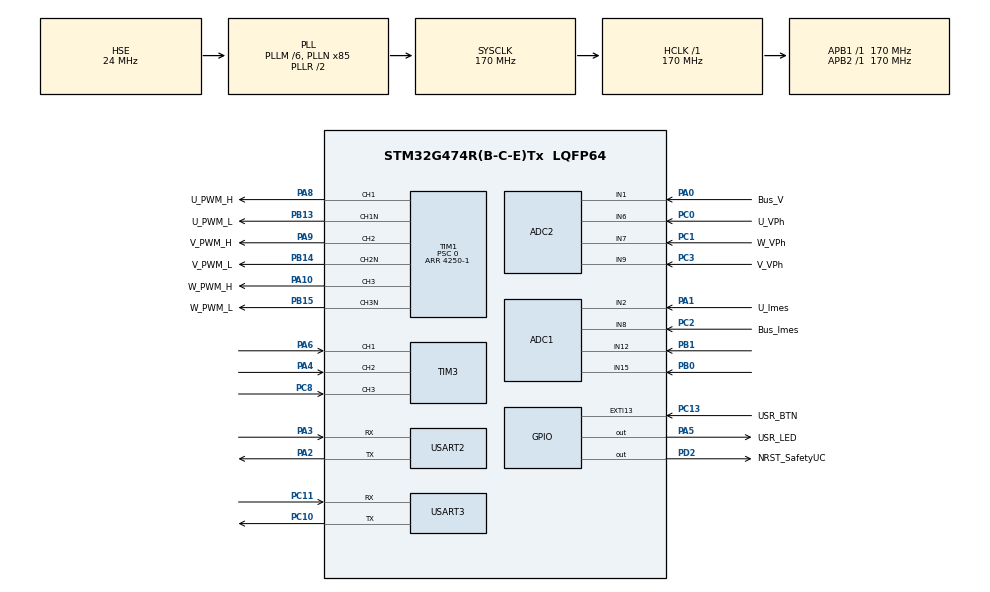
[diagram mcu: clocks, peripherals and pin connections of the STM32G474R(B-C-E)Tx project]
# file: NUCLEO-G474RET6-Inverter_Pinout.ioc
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ADC1.Channel-0\#ChannelRegularConversion=ADC_CHANNEL_8
ADC1.ClockPrescaler=ADC_CLOCK_ASYNC_DIV256
ADC1.ContinuousConvMode=ENABLE
ADC1.DMAContinuousRequests=ENABLE
ADC1.ExternalTrigConv=ADC_EXTERNALTRIG_T1_CC1
ADC1.NbrOfConversionFlag=1
ADC1.OffsetNumber-0\#ChannelRegularConversion=ADC_OFFSET_NONE
ADC1.Rank-0\#ChannelRegularConversion=1
ADC1.SamplingTime-0\#ChannelRegularConversion=ADC_SAMPLETIME_2CYCLES_5
ADC1.master=1
ADC2.Channel-0\#ChannelRegularConversion=ADC_CHANNEL_6
ADC2.ClockPrescaler=ADC_CLOCK_ASYNC_DIV256
ADC2.NbrOfConversionFlag=1
ADC2.OffsetNumber-0\#ChannelRegularConversion=ADC_OFFSET_NONE
ADC2.Rank-0\#ChannelRegularConversion=1
ADC2.SamplingTime-0\#ChannelRegularConversion=ADC_SAMPLETIME_2CYCLES_5
Dma.ADC1.0.Direction=DMA_PERIPH_TO_MEMORY
Dma.ADC1.0.EventEnable=DISABLE
Dma.ADC1.0.Instance=DMA1_Channel1
Dma.ADC1.0.MemDataAlignment=DMA_MDATAALIGN_WORD
Dma.ADC1.0.MemInc=DMA_MINC_ENABLE
Dma.ADC1.0.Mode=DMA_NORMAL
Dma.ADC1.0.PeriphDataAlignment=DMA_PDATAALIGN_WORD
Dma.ADC1.0.PeriphInc=DMA_PINC_DISABLE
Dma.ADC1.0.Polarity=HAL_DMAMUX_REQ_GEN_RISING
Dma.ADC1.0.Priority=DMA_PRIORITY_LOW
Dma.ADC1.0.RequestNumber=1
Dma.ADC1.0.SignalID=NONE
Dma.ADC1.0.SyncEnable=DISABLE
Dma.ADC1.0.SyncPolarity=HAL_DMAMUX_SYNC_NO_EVENT
Dma.ADC1.0.SyncRequestNumber=1
Dma.ADC1.0.SyncSignalID=NONE
Dma.Request0=ADC1
Mcu.Family=STM32G4
Mcu.Name=STM32G474R(B-C-E)Tx
Mcu.Package=LQFP64
NVIC.DMA1_Channel1_IRQn=true\:0\:0\:false\:false\:true\:false\:true\:true
NVIC.EXTI15_10_IRQn=true\:0\:0\:false\:false\:true\:true\:true\:true
NVIC.PriorityGroup=NVIC_PRIORITYGROUP_4
NVIC.TIM6_DAC_IRQn=true\:15\:0\:false\:false\:true\:false\:true\:true
NVIC.TimeBase=TIM6_DAC_IRQn
NVIC.TimeBaseIP=TIM6
NVIC.USART2_IRQn=true\:0\:0\:false\:false\:true\:true\:true\:true
NVIC.USART3_IRQn=true\:0\:0\:false\:false\:true\:true\:true\:true
PA0.GPIO_Label=Bus_V
PA0.Mode=IN1-Single-Ended
PA0.Signal=ADC2_IN1
PA1.GPIO_Label=U_Imes
PA1.Mode=IN2-Single-Ended
PA1.Signal=ADC1_IN2
PA10.GPIO_Label=W_PWM_H
PA10.Signal=S_TIM1_CH3
PA13.GPIO_Label=T_SWDIO
PA13.Mode=Trace_Asynchronous_SW
PA13.Signal=SYS_JTMS-SWDIO
PA14.GPIO_Label=T_SWCLK
PA14.Mode=Trace_Asynchronous_SW
PA14.Signal=SYS_JTCK-SWCLK
PA2.Mode=Asynchronous
PA2.Signal=USART2_TX
PA3.Mode=Asynchronous
PA3.Signal=USART2_RX
PA4.Signal=S_TIM3_CH2
PA5.GPIO_Label=USR_LED
PA5.Signal=GPIO_Output
PA6.Signal=S_TIM3_CH1
PA8.GPIO_Label=U_PWM_H
PA8.Signal=S_TIM1_CH1
PA9.GPIO_Label=V_PWM_H
PA9.Signal=S_TIM1_CH2
PB0.Mode=IN15-Single-Ended
PB0.Signal=ADC1_IN15
PB1.Mode=IN12-Single-Ended
PB1.Signal=ADC1_IN12
PB13.GPIO_Label=U_PWM_L
PB13.Mode=PWM Generation1 CH1 CH1N
PB13.Signal=TIM1_CH1N
PB14.GPIO_Label=V_PWM_L
PB14.Mode=PWM Generation2 CH2 CH2N
PB14.Signal=TIM1_CH2N
PB15.GPIO_Label=W_PWM_L
PB15.Mode=PWM Generation3 CH3 CH3N
PB15.Signal=TIM1_CH3N
PB3.GPIO_Label=T_SWO
PB3.Mode=Trace_Asynchronous_SW
PB3.Signal=SYS_JTDO-SWO
PC0.GPIO_Label=U_VPh
PC0.Mode=IN6-Single-Ended
PC0.Signal=ADC2_IN6
PC1.GPIO_Label=W_VPh
PC1.Mode=IN7-Single-Ended
PC1.Signal=ADC2_IN7
PC10.Mode=Asynchronous
PC10.Signal=USART3_TX
PC11.Mode=Asynchronous
PC11.Signal=USART3_RX
PC13.GPIO_Label=USR_BTN
PC13.Signal=GPXTI13
PC14-OSC32_IN.Mode=LSE-External-Oscillator
PC14-OSC32_IN.Signal=RCC_OSC32_IN
PC15-OSC32_OUT.Mode=LSE-External-Oscillator
PC15-OSC32_OUT.Signal=RCC_OSC32_OUT
PC2.GPIO_Label=Bus_Imes
PC2.Mode=IN8-Single-Ended
PC2.Signal=ADC1_IN8
PC3.GPIO_Label=V_VPh
PC3.Mode=IN9-Single-Ended
PC3.Signal=ADC2_IN9
PC8.Signal=S_TIM3_CH3
PD2.GPIO_Label=NRST_SafetyUC
PD2.Signal=GPIO_Output
PF0-OSC_IN.Mode=HSE-External-Oscillator
PF0-OSC_IN.Signal=RCC_OSC_IN
PF1-OSC_OUT.Mode=HSE-External-Oscillator
PF1-OSC_OUT.Signal=RCC_OSC_OUT
ProjectManager.HeapSize=0x200
ProjectManager.StackSize=0x400
ProjectManager.TargetToolchain=STM32CubeIDE
RCC.ADC12Freq_Value=170000000
RCC.ADC345Freq_Value=170000000
RCC.AHBFreq_Value=170000000
RCC.APB1Freq_Value=170000000
RCC.APB1TimFreq_Value=170000000
RCC.APB2Freq_Value=170000000
RCC.APB2TimFreq_Value=170000000
RCC.CortexFreq_Value=170000000
RCC.EXTERNAL_CLOCK_VALUE=12288000
RCC.HCLKFreq_Value=170000000
RCC.HSE_VALUE=24000000
RCC.HSI48_VALUE=48000000
RCC.HSI_VALUE=16000000
RCC.PLLM=RCC_PLLM_DIV6
RCC.PLLN=85
RCC.PLLSourceVirtual=RCC_PLLSOURCE_HSE
RCC.RTCClockSelection=RCC_RTCCLKSOURCE_LSE
RCC.SYSCLKFreq_VALUE=170000000
RCC.SYSCLKSource=RCC_SYSCLKSOURCE_PLLCLK
RCC.USBFreq_Value=170000000
RCC.VCOOutputFreq_Value=340000000
SH.S_TIM1_CH1.0=TIM1_CH1,PWM Generation1 CH1 CH1N
SH.S_TIM1_CH2.0=TIM1_CH2,PWM Generation2 CH2 CH2N
SH.S_TIM1_CH3.0=TIM1_CH3,PWM Generation3 CH3 CH3N
SH.S_TIM3_CH1.0=TIM3_CH1,Xored_Inputs_Hall_Sensor_Interface
SH.S_TIM3_CH2.0=TIM3_CH2,Xored_Inputs_Hall_Sensor_Interface
SH.S_TIM3_CH3.0=TIM3_CH3,Xored_Inputs_Hall_Sensor_Interface
TIM1.Channel-PWM\ Generation1\ CH1\ CH1N=TIM_CHANNEL_1
TIM1.Channel-PWM\ Generation2\ CH2\ CH2N=TIM_CHANNEL_2
TIM1.Channel-PWM\ Generation3\ CH3\ CH3N=TIM_CHANNEL_3
TIM1.CounterMode=TIM_COUNTERMODE_CENTERALIGNED1
TIM1.DeadTime=15
TIM1.PeriodNoDither=4250-1
TIM1.Prescaler=0
TIM1.TIM_MasterOutputTrigger=TIM_TRGO_OC1REF
USART2.VirtualMode-Asynchronous=VM_ASYNC
USART3.VirtualMode-Asynchronous=VM_ASYNC
VP_SYS_VS_DBSignals.Mode=DisableDeadBatterySignals
VP_SYS_VS_tim6.Mode=TIM6
board=NUCLEO-G474RE

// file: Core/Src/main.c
/* USER CODE BEGIN Header */
/**
 ******************************************************************************
 * @file           : main.c
 * @brief          : Main program body
 ******************************************************************************
 * @attention
 *
 * Copyright (c) 2023 STMicroelectronics.
 * All rights reserved.
 *
 * This software is licensed under terms that can be found in the LICENSE file
 * in the root directory of this software component.
 * If no LICENSE file comes with this software, it is provided AS-IS.
 *
 ******************************************************************************
 */
/* USER CODE END Header */
#include "main.h"
#include "adc.h"
#include "dma.h"
#include "tim.h"
#include "usart.h"
#include "gpio.h"

/* USER CODE BEGIN Includes */
#include "mylibs/shell.h"
/* USER CODE END Includes */

/* USER CODE BEGIN PV */
uint32_t buffer = 0;
/* USER CODE END PV */

void SystemClock_Config(void);

/* USER CODE BEGIN 0 */
int __io_putchar(int ch) {
	HAL_UART_Transmit(&huart2, (uint8_t *)&ch, 1, HAL_MAX_DELAY);
	return ch;
}
/* USER CODE END 0 */

int main(void)
{

  /* MCU Configuration--------------------------------------------------------*/

  /* Reset of all peripherals, Initializes the Flash interface and the Systick. */
  HAL_Init();

  /* USER CODE BEGIN Init */
	//Start_PWM_Signals();
  /* USER CODE END Init */

  /* Configure the system clock */
  SystemClock_Config();

  /* Initialize all configured peripherals */
  MX_GPIO_Init();
  MX_DMA_Init();
  MX_ADC2_Init();
  MX_ADC1_Init();
  MX_TIM1_Init();
  MX_TIM3_Init();
  MX_USART2_UART_Init();
  MX_USART3_UART_Init();
  /* USER CODE BEGIN 2 */
	Shell_Init();
	HAL_ADC_Start_DMA(&hadc1,(uint32_t*)&buffer,1);

  /* USER CODE END 2 */

  /* Infinite loop */
  /* USER CODE BEGIN WHILE */
	while (1)
	{
		Shell_Loop();
    /* USER CODE END WHILE */

	}
}

void SystemClock_Config(void)
{
  RCC_OscInitTypeDef RCC_OscInitStruct = {0};
  RCC_ClkInitTypeDef RCC_ClkInitStruct = {0};

  /** Configure the main internal regulator output voltage
  */
  HAL_PWREx_ControlVoltageScaling(PWR_REGULATOR_VOLTAGE_SCALE1_BOOST);

  /** Initializes the RCC Oscillators according to the specified parameters
  * in the RCC_OscInitTypeDef structure.
  */
  RCC_OscInitStruct.OscillatorType = RCC_OSCILLATORTYPE_HSE;
  RCC_OscInitStruct.HSEState = RCC_HSE_ON;
  RCC_OscInitStruct.PLL.PLLState = RCC_PLL_ON;
  RCC_OscInitStruct.PLL.PLLSource = RCC_PLLSOURCE_HSE;
  RCC_OscInitStruct.PLL.PLLM = RCC_PLLM_DIV6;
  RCC_OscInitStruct.PLL.PLLN = 85;
  RCC_OscInitStruct.PLL.PLLP = RCC_PLLP_DIV2;
  RCC_OscInitStruct.PLL.PLLQ = RCC_PLLQ_DIV2;
  RCC_OscInitStruct.PLL.PLLR = RCC_PLLR_DIV2;
  if (HAL_RCC_OscConfig(&RCC_OscInitStruct) != HAL_OK)
  {
    Error_Handler();
  }

  /** Initializes the CPU, AHB and APB buses clocks
  */
  RCC_ClkInitStruct.ClockType = RCC_CLOCKTYPE_HCLK|RCC_CLOCKTYPE_SYSCLK
                              |RCC_CLOCKTYPE_PCLK1|RCC_CLOCKTYPE_PCLK2;
  RCC_ClkInitStruct.SYSCLKSource = RCC_SYSCLKSOURCE_PLLCLK;
  RCC_ClkInitStruct.AHBCLKDivider = RCC_SYSCLK_DIV1;
  RCC_ClkInitStruct.APB1CLKDivider = RCC_HCLK_DIV1;
  RCC_ClkInitStruct.APB2CLKDivider = RCC_HCLK_DIV1;

  if (HAL_RCC_ClockConfig(&RCC_ClkInitStruct, FLASH_LATENCY_4) != HAL_OK)
  {
    Error_Handler();
  }
}

void HAL_TIM_PeriodElapsedCallback(TIM_HandleTypeDef *htim)
{
  if (htim->Instance == TIM6) {
    HAL_IncTick();
  }
}

void Error_Handler(void)
{
	__disable_irq();
	while (1)
	{
	}
}
